# AT32F403A register map
Vendor: Keil; Series: AT32F403A; File version: 1.0
CPU: CM4 r0p1, little endian, no MPU, FPU, 4 interrupt priority bits
Registers are 32-bit, read-write, reset 0x0 unless marked. A register's access mark holds for its fields unless they carry their own. Offsets are from the block's base; [hi:lo] are bit positions; lines under a group give offsets from that group; {n}, {i} and the like mark numbered series.

## CAN1 — Can controller area network
Base 0x40006400
Same registers: CAN2 0x40006800
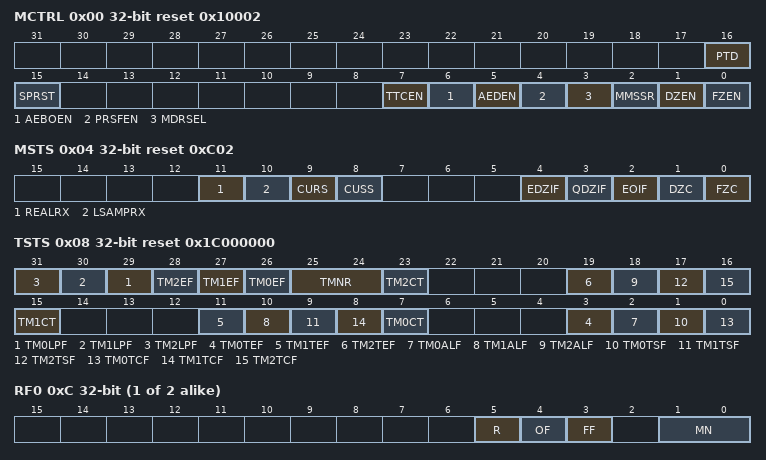
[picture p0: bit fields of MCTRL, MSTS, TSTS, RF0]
0x00 MCTRL reset 0x10002 — Main control register
  [16] PTD — Prohibit transmission when debug
    0=Work (Transmission works during debug); 1=Prohibited (Transmission is prohibited during debug. Receive FIFO can be still accessible normally)
  [15] SPRST write-1-sets — Software partial reset
    on read: 0=Normal; 1=Reset (Software partial reset) | on write: 1=Reset (Software partial reset)
  [7] TTCEN — Time triggered communication mode enable
    on read: 0=Disabled (Time triggered communication mode is disabled); 1=Enabled (Time triggered communication mode is enabled) | on write: 0=Disable (Time triggered communication mode disable); 1=Enable (Time triggered communication mode enable)
  [6] AEBOEN — Automatic exit bus-off enable
    on read: 0=Disabled (Automatic exit bus-off is disabled); 1=Enabled (Automatic exit bus-off is enabled) | on write: 0=Disable (Automatic exit bus-off disable); 1=Enable (Automatic exit bus-off enable)
  [5] AEDEN — Automatic exit doze mode enable
    on read: 0=Disabled (Automatic exit doze mode is disabled); 1=Enabled (Automatic exit doze mode is enabled) | on write: 0=Disable (Automatic exit doze mode disable); 1=Enable (Automatic exit doze mode enable)
  [4] PRSFEN — Prohibit retransmission when sending fails enable
    on read: 0=Disabled (Prohibit retransmission is disabled when sending fails enable); 1=Enabled (Prohibit retransmission is enabled when sending fails enable) | on write: 0=Disable (Prohibit retransmission disable); 1=Enable (Prohibit retransmission enable)
  [3] MDRSEL — Message discarding rule select when overflow
    0=Previous (The previous message is discarded); 1=Incoming (The new incoming message is discarded)
  [2] MMSSR — Multiple message sending sequence rule
    0=SmallestIdentifer (The message with the smallest identifier is first transmitted); 1=FirstRequestOrder (The message with the first request order is first transmitted)
  [1] DZEN — Doze mode enable
    on read: 0=Disabled (Doze mode is disabled); 1=Enabled (Doze mode is enabled) | on write: 0=Disable (Doze mode disable); 1=Enable (Doze mode enable)
  [0] FZEN — Freeze mode enable
    on read: 0=Disabled (Freeze mode is disabled); 1=Enabled (Freeze mode is enabled) | on write: 0=Disable (Freeze mode disable); 1=Enable (Freeze mode enable)
0x04 MSTS reset 0xC02 — Main status register
  [11] REALRX ro — Real time level of RX pin
    0=Low; 1=High
  [10] LSAMPRX ro — Last sample level of RX pin
    0=Low; 1=High
  [9] CURS ro — Currently receiving status
    0=Idle (No reception occurs); 1=InProgress (Reception is in progress)
  [8] CUSS ro — Currently sending status
    0=Idle (No transmit occurs); 1=InProgress (Transmit is in progress)
  [4] EDZIF write-1-clears — Enter doze mode interrupt flag
    on read: 0=NotEnter (Sleep mode is not entered or no condition for flag set); 1=EnterSleep (Sleep mode is entered) | on write: 1=Clear enter doze flag
  [3] QDZIF write-1-clears — Quit doze mode interrupt flag
    on read: 0=InSleep (Sleep mode is not left or no condition for exit); 1=SleepExit (Sleep mode has been left or exit condition has generated) | on write: 1=Clear exit doze flag
  [2] EOIF write-1-clears — Error occur Interrupt flag
    on read: 0=No error interrupt or no condition for error interrupt flag; 1=Error interrupt is generated | on write: 1=Clear error flag
  [1] DZC ro — Doze mode confirm
    0=NotSleep (The CAN is not in Sleep mode); 1=Sleep (The CAN is in Sleep mode)
  [0] FZC ro — Freeze mode confirm
    0=NotFreeze (The CAN is not in Freeze mode); 1=Freeze (The CAN is in Freeze mode)
0x08 TSTS reset 0x1C000000 — Transmit status register
  [n+29] TM{n}LPF (n=0..2) ro — Transmit mailbox {n} lowest priority flag
    0=NotLowest (Mailbox is not given the lowest priority); 1=Lowest (Mailbox is given the lowest priority)
  [n+26] TM{n}EF (n=0..2) ro — Transmit mailbox {n} empty flag
    0=NotEmpty (Transmission is pending in the mailbox); 1=Empty (No transmission is pending in the mailbox)
  [25:24] TMNR ro — Transmit Mailbox number record
  [8n+7] TM{n}CT (n=0..2) write-1-sets — Transmit mailbox {n} cancel transmission
    on read: 0=NoCancelling (No effect); 1=Cancelling (Mailbox cancel transmit) | on write: 1=Abort (Mailbox cancel transmit)
  [8n+3] TM{n}TEF (n=0..2) write-1-clears — Transmit mailbox {n} transmission error flag
    on read: 0=NoError; 1=Error (Mailbox transmission error) | on write: 1=Clear transmission error flag
  [8n+2] TM{n}ALF (n=0..2) write-1-clears — Transmit mailbox {n} arbitration lost flag
    on read: 0=NoLost (No arbitration lost); 1=Lost (Transmit mailbox arbitration lost) | on write: 1=Clear arbitration lost flag
  [8n+1] TM{n}TSF (n=0..2) write-1-clears — Transmit mailbox {n} transmission success flag
    on read: 0=Failed (Transmission in progress); 1=Successful (Transmission was successful) | on write: 1=Clear transmission success flag
  [8n] TM{n}TCF (n=0..2) write-1-clears — Transmit mailbox {n} transmission complete flag
    on read: 0=InProgress (Transmission in progress); 1=Completed (Transmission completed) | on write: 1=Clear transmission completed flag
{0xC+4i} RF{i} (i=0..1) — Receive FIFO {i} register
  [5] R write-1-sets — Receive FIFO release
    on read: 0=Released (FIFO is released); 1=Releasing (FIFO release in progress) | on write: 1=Release FIFO
  [4] OF write-1-clears — Receive FIFO overflow flag
    on read: 0=NoOverflow; 1=Overflow (Receive FIFO overflow) | on write: 1=Clear overflow flag
  [3] FF write-1-clears — Receive FIFO full flag
    on read: 0=NotFull (Receive FIFO is not full); 1=Full (Receive FIFO is full) | on write: 1=Clear full flag
  [1:0] MN ro — Receive FIFO message num
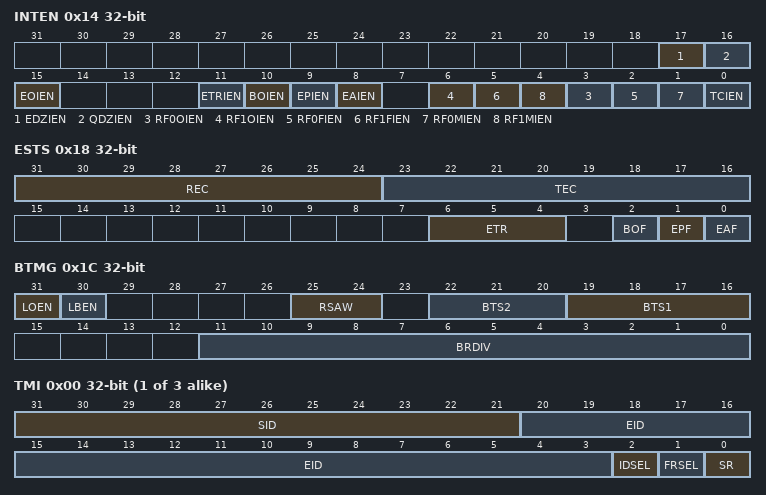
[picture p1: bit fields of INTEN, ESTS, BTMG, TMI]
0x14 INTEN — Interrupt enable register
  [17] EDZIEN — Enter doze mode interrupt enable
    on read: 0=Disabled (Enter doze mode interrupt is disabled); 1=Enabled (Enter doze mode interrupt is enabled) | on write: 0=Disable (Enter doze mode interrupt disable); 1=Enable (Enter doze mode interrupt enable)
  [16] QDZIEN — Quit doze mode interrupt enable
    on read: 0=Disabled (Quit doze mode interrupt is disabled); 1=Enabled (Quit doze mode interrupt is enabled) | on write: 0=Disable (Quit doze mode interrupt disable); 1=Enable (Quit doze mode interrupt enable)
  [15] EOIEN — Error occur interrupt enable
    on read: 0=Disabled (Error occur interrupt is disabled); 1=Enabled (Error occur interrupt is enabled) | on write: 0=Disable (Error occur interrupt disable); 1=Enable (Error occur interrupt enable)
  [11] ETRIEN — Error type record interrupt enable
    on read: 0=Disabled (Error type record interrupt is disabled); 1=Enabled (Error type record interrupt is enabled) | on write: 0=Disable (Error type record interrupt disable); 1=Enable (Error type record interrupt enable)
  [10] BOIEN — Bus-off interrupt enable
    on read: 0=Disabled (Bus-off interrupt is disabled); 1=Enabled (Bus-off interrupt is enabled) | on write: 0=Disable (Bus-off interrupt disable); 1=Enable (Bus-off interrupt enable)
  [9] EPIEN — Error passive interrupt enable
    on read: 0=Disabled (Error passive interrupt is disabled); 1=Enabled (Error passive interrupt is enabled) | on write: 0=Disable (Error passive interrupt disable); 1=Enable (Error passive interrupt enable)
  [8] EAIEN — Error active interrupt enable
    on read: 0=Disabled (Error active interrupt is disabled); 1=Enabled (Error active interrupt is enabled) | on write: 0=Disable (Error active interrupt disable); 1=Enable (Error active interrupt enable)
  [3n+3] RF{n}OIEN (n=0..1) — Receive FIFO {n} overflow interrupt enable
    on read: 0=Disabled (Receive FIFO overflow interrupt is disabled); 1=Enabled (Receive FIFO overflow interrupt is enabled) | on write: 0=Disable (Receive FIFO overflow interrupt disable); 1=Enable (Receive FIFO overflow interrupt enable)
  [3n+2] RF{n}FIEN (n=0..1) — Receive FIFO {n} full interrupt enable
    on read: 0=Disabled (Receive FIFO full interrupt is disabled); 1=Enabled (Receive FIFO full interrupt is enabled) | on write: 0=Disable (Receive FIFO full interrupt disable); 1=Enable (Receive FIFO full interrupt enable)
  [3n+1] RF{n}MIEN (n=0..1) — FIFO {n} receive message interrupt enable
    on read: 0=Disabled (FIFO receive message interrupt is disabled); 1=Enabled (FIFO receive message interrupt is enabled) | on write: 0=Disable (FIFO receive message interrupt disable); 1=Enable (FIFO receive message interrupt enable)
  [0] TCIEN — Transmission complete interrupt enable
    on read: 0=Disabled (Transmit mailbox empty interrupt is disabled); 1=Enabled (Transmit mailbox empty interrupt is enabled) | on write: 0=Disable (Transmit mailbox empty interrupt disable); 1=Enable (Transmit mailbox empty interrupt enable)
0x18 ESTS — Error status register
  [31:24] REC ro — Receive error counter
  [23:16] TEC ro — Transmit error counter
  [6:4] ETR — Error type record
    0=NoError; 1=Bit stuffing error; 2=Format error; 3=Acknowledgement error; 4=Recessive bit error; 5=Dominant bit error; 6=CRC (CRC error); 7=Software (Set by software)
  [2] BOF ro — Bus-off flag
    0=NotEntered (Bus-off state is not entered); 1=Entered (Bus-off state is entered)
  [1] EPF ro — Error passive flag
    0=NotEntered (Error passive state is not entered); 1=Entered (Error passive state is entered)
  [0] EAF ro — Error active flag
    0=NotEntered (Error active state is not entered); 1=Entered (Error active state is entered)
0x1C BTMG — Bit timing register
  [31] LOEN — Listen-Only mode
    on read: 0=Disabled (Listen-Only mode is disabled); 1=Enabled (Listen-Only mode is enabled) | on write: 0=Disable (Listen-Only mode disable); 1=Enable (Listen-Only mode enable)
  [30] LBEN — Loop back mode
    on read: 0=Disabled (Loop back mode is disabled); 1=Enabled (Loop back mode is enabled) | on write: 0=Disable (Loop back mode disable); 1=Enable (Loop back mode enable)
  [25:24] RSAW — Resynchronization adjust width
  [22:20] BTS2 — Bit time segment 2
  [19:16] BTS1 — Bit time segment 1
  [11:0] BRDIV — Baud rate division
{0x180+0x10*i} Mailbox{i} (i=0..2) group — Mailbox {i}
  0x00 TMI — Transmit mailbox identifier register
    [31:21] SID — Transmit mailbox standard identifier or extended identifier high bytes
    [20:3] EID — Ttransmit mailbox extended identifier
    [2] IDSEL — Transmit mailbox identifier type select
      0=Standard identifier; 1=Extended identifier
    [1] FRSEL — Transmit mailbox frame type select
      0=Data frame; 1=Remote frame
    [0] SR write-1-sets — Transmit mailbox send request
      on read: 0=InProgress (Transmission in progress); 1=Completed (Transmission completed) | on write: 1=Transmit request
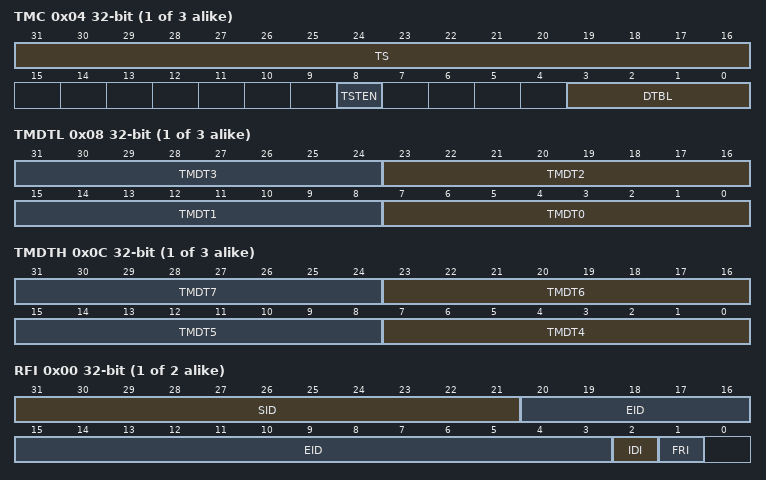
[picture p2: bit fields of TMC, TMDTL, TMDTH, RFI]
  0x04 TMC — Transmit mailbox data length and time stamp register
    [31:16] TS — Transmit mailbox time stamp
    [8] TSTEN — Transmit mailbox time stamp transmit enable
      on read: 0=Disabled (Mailbox time stamp transmit is disabled); 1=Enabled (Mailbox time stamp transmit is enabled) | on write: 0=Disable (Mailbox time stamp transmit disable); 1=Enable (Mailbox time stamp transmit enable)
    [3:0] DTBL — Transmit mailbox data byte length
  0x08 TMDTL — Transmit mailbox data low register
    [8n+7:8n] TMDT{n} (n=0..3) — Transmit mailbox data byte {n}
  0x0C TMDTH — Transmit mailbox data high register
    [8n-25:8n-32] TMDT{n} (n=4..7) — Transmit mailbox data byte {n}
{0x1B0+0x10*i} FIFO{i} (i=0..1) group — FIFO {i}
  0x00 RFI ro — Receive FIFO mailbox identifier register
    [31:21] SID — Receive FIFO standard identifier or receive FIFO extended identifier
    [20:3] EID — Receive FIFO extended identifier
    [2] IDI — Receive FIFO identifier type indication
      0=Standard identifier; 1=Extended identifier
    [1] FRI — Receive FIFO frame type indication
      0=Data frame; 1=Remote frame
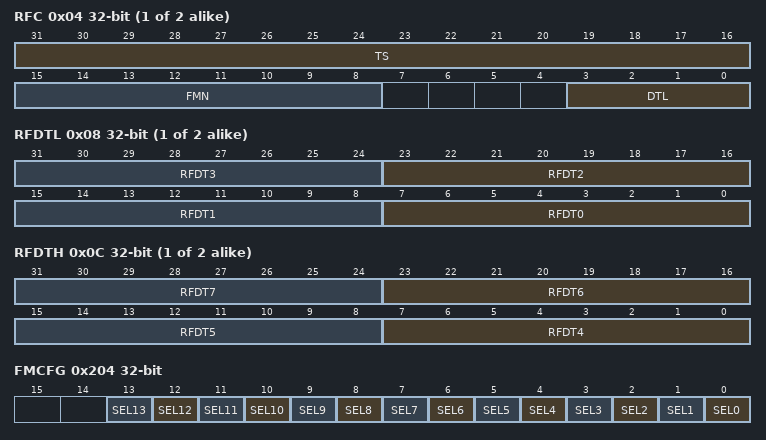
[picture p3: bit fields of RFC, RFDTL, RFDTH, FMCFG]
  0x04 RFC ro — Receive FIFO mailbox data length and time stamp register
    [31:16] TS — Receive FIFO time stamp
    [15:8] FMN — Receive FIFO filter match number
    [3:0] DTL — Receive FIFO data length
  0x08 RFDTL ro — Receive FIFO mailbox data low register
    [8n+7:8n] RFDT{n} (n=0..3) — Receive FIFO data byte {n}
  0x0C RFDTH ro — Receive FIFO mailbox data high register
    [8n-25:8n-32] RFDT{n} (n=4..7) — Receive FIFO data byte {n}
0x200 FCTRL — Filter control register
  [0] FCS — Filters configure switch
    0=Active (Filter bank is active); 1=Configuration (Filter bank is in configuration mode)
0x204 FMCFG — Filter mode config register
  [n] SEL{n} (n=0..13) — Filter mode select
    0=Mask (Identifier mask mode); 1=List (Identifier list mode)
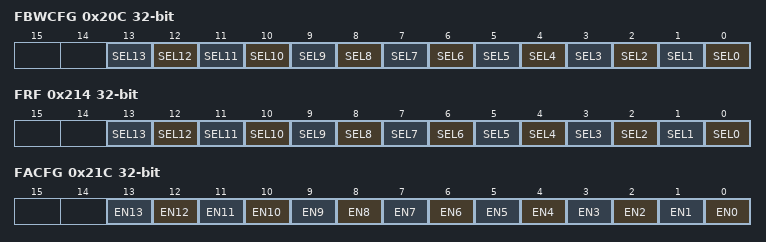
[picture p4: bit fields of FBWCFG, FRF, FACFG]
0x20C FBWCFG — Filter bit width config register
  [n] SEL{n} (n=0..13) — Filter bit width select
    0=Dual 16-bit; 1=Single 32-bit
0x214 FRF — Filter related FIFO register
  [n] SEL{n} (n=0..13) — Filter relation FIFO select
    0=Dual (Associated with FIFO0); 1=Single (Associated with FIFO1)
0x21C FACFG — Filter activate configuration register
  [n] EN{n} (n=0..13) — Filter activate enable
    on read: 0=Disabled (Filter is disabled); 1=Enabled (Filter is enabled) | on write: 0=Disable (Filter disable); 1=Enable (Filter enable)
{0x240+8i} FilterBank{i} (i=0..13) group — Filter Bank {i}
  0x00 FFB{j} (j=1..2; step 0x4) — CAN filter bank filter bit register {j}
